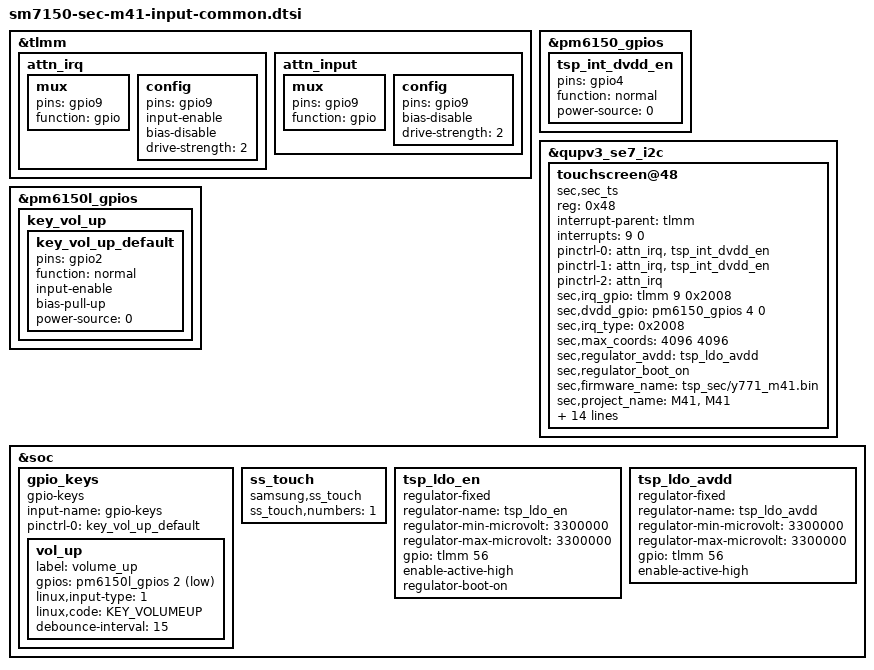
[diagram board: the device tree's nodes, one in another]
/* Copyright (c) 2016-2017, The Linux Foundation. All rights reserved.
 *
 * This program is free software; you can redistribute it and/or modify
 * it under the terms of the GNU General Public License version 2 and
 * only version 2 as published by the Free Software Foundation.
 *
 * This program is distributed in the hope that it will be useful,
 * but WITHOUT ANY WARRANTY; without even the implied warranty of
 * MERCHANTABILITY or FITNESS FOR A PARTICULAR PURPOSE.  See the
 * GNU General Public License for more details.
 */

#include <dt-bindings/input/input.h>

&tlmm {
   attn_irq: attn_irq {
		mux {
			pins = "gpio9";
			function = "gpio";
		};
		
		config {
			pins = "gpio9";
			input-enable;
			bias-disable; /* No PULL */
			drive-strength = <2>;
		};
	};	
	attn_input: attn_input {
		mux {
			pins = "gpio9";
			function = "gpio";
		};
		
		config {
			pins = "gpio9";
			/*input-enable;*/
			bias-disable;
			drive-strength = <2>;
		};
	};
};

&pm6150_gpios {
	tsp_int_dvdd_en: tsp_int_dvdd_en {
		pins = "gpio4";
		function = "normal";
		power-source = <0>;
	};
};


&qupv3_se7_i2c {
	status = "ok";
	
	touchscreen@48 {
		status = "ok";
		compatible = "sec,sec_ts";
		reg = <0x48>;
		interrupt-parent = <&tlmm>;
		interrupts = <9 0>;
		pinctrl-names = "default", "on_state", "off_state";
		pinctrl-0 = <&attn_irq &tsp_int_dvdd_en>;
		pinctrl-1 = <&attn_irq &tsp_int_dvdd_en>;
		pinctrl-2 = <&attn_irq>;
		sec,irq_gpio = <&tlmm 9 0x2008>;
		sec,dvdd_gpio = <&pm6150_gpios 4 0>;    /* tsp_dvdd_en PMIC GPIO 4, tsp_ldo_dvdd regulator */
		sec,irq_type = <0x2008>;
		sec,max_coords = <4096 4096>; /* x y */
		sec,regulator_avdd = "tsp_ldo_avdd";
		sec,regulator_boot_on;
		sec,firmware_name = "tsp_sec/y771_m41.bin";
		sec,project_name = "M41", "M41";
		sec,tclm_level = <1>;
		sec,afe_base = <0x00>;
		support_dex_mode;
		sec,i2c-burstmax = <0xffff>;
		sec,ss_touch_num = <1>;
		enable_settings_aot;
		sec,area-size = <132 266 341>;
		support_ear_detect_mode;
		sync-reportrate-120 = "Y";
		support_fod;
		support_fod_gesture;
		support_open_short_test;
		support_mis_calibration_test;
		sec,bringup = <3>;
	};	
};

/delete-node/&key_vol_up_default;
&pm6150l_gpios {
	key_vol_up {
		key_vol_up_default: key_vol_up_default {
			pins = "gpio2";
			function = "normal";
			input-enable;
			bias-pull-up;
			power-source = <0>;
		};
	};
};

&soc {
	/delete-node/gpio_keys;
	gpio_keys {
		status = "ok";
		compatible = "gpio-keys";
		input-name = "gpio-keys";

		pinctrl-names = "default";
		pinctrl-0 = <&key_vol_up_default>;

		vol_up {
			label = "volume_up";
			gpios = <&pm6150l_gpios 2 0x1>;
			linux,input-type = <1>;
			linux,code = <KEY_VOLUMEUP>;
			debounce-interval = <15>;
		};
	};

	ss_touch {
		compatible = "samsung,ss_touch";
		ss_touch,numbers = <1>;
	};

	tsp_ldo_en {
		compatible = "regulator-fixed";
		regulator-name = "tsp_ldo_en";
		regulator-min-microvolt = <3300000>;
		regulator-max-microvolt = <3300000>;
		gpio = <&tlmm 56 0>;
		enable-active-high;
		regulator-boot-on;
	};
	
	tsp_ldo_avdd {
		compatible = "regulator-fixed";
		regulator-name = "tsp_ldo_avdd";
		regulator-min-microvolt = <3300000>;
		regulator-max-microvolt = <3300000>;
		gpio = <&tlmm 56 0>;
		enable-active-high;
	};
};
